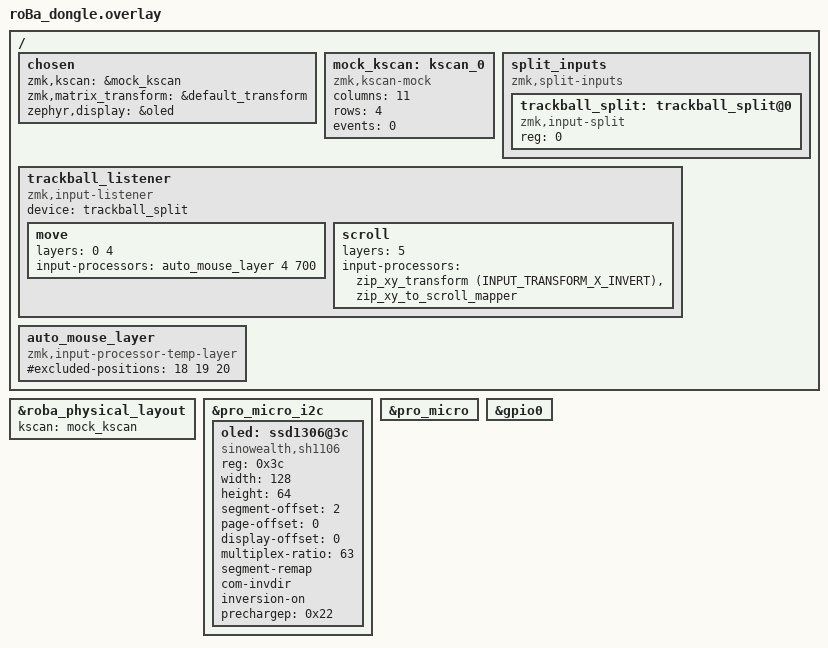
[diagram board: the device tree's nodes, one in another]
#include <dt-bindings/zmk/matrix_transform.h>
#include <dt-bindings/zmk/input_transform.h>
#include <input/processors.dtsi>
#include "roBa.dtsi"

/ {
    chosen {
        zmk,kscan = &mock_kscan;
        zmk,matrix_transform = &default_transform;
        zephyr,display = &oled;
    };

    mock_kscan: kscan_0 {
        compatible = "zmk,kscan-mock";
        columns = <11>;
        rows = <4>;
        events = <0>;
    };

    /* トラックボール信号の受け皿 (ドングル側) */
    split_inputs {
        compatible = "zmk,split-inputs";
        #address-cells = <1>;
        #size-cells = <0>;
        
        trackball_split: trackball_split@0 {
            compatible = "zmk,input-split";
            reg = <0>;
        };
    };

    /* リスナー定義 (wave10-F: restore the original automouse/scroll
     * behaviour in ZMK-main input-processor form. The external-driver
     * properties automouse-layer=<4> / scroll-layers=<5> and
     * CONFIG_PMW3610_AUTOMOUSE_TIMEOUT_MS=700 were lost in the move
     * to the in-tree driver; layer indices are this repo's keymap
     * order: 0 default, 4 MOUSE, 5 SCROLL.) */
    trackball_listener {
        compatible = "zmk,input-listener";
        device = <&trackball_split>;
        status = "okay";

        move {
            layers = <0 4>;
            input-processors = <&auto_mouse_layer 4 700>;
        };

        scroll {
            layers = <5>;
            /* original: CONFIG_PMW3610_INVERT_SCROLL_X=y */
            input-processors = <&zip_xy_transform (INPUT_TRANSFORM_X_INVERT)>, <&zip_xy_to_scroll_mapper>;
        };
    };

    auto_mouse_layer: auto_mouse_layer {
        compatible = "zmk,input-processor-temp-layer";
        #input-processor-cells = <2>;
        /* Mouse-button positions in the MOUSE layer (MB1/MB3/MB2 at
         * positions 18/19/20) must not dismiss the temporary layer. */
        #excluded-positions = <18 19 20>;
    };
};

/* The shared physical layout points at &kscan0, which the dongle does
 * not have; point it at the mock kscan instead (wave10-F). Without
 * this, the restored physical layout breaks the dongle build and
 * ZMK Studio on the dongle has no layout. */
&roba_physical_layout {
    kscan = <&mock_kscan>;
};

&pro_micro_i2c {
    status = "okay";
    oled: ssd1306@3c {
        compatible = "sinowealth,sh1106";
        reg = <0x3c>;
        width = <128>;
        height = <64>;
        segment-offset = <2>;
        page-offset = <0>;
        display-offset = <0>;
        multiplex-ratio = <63>;
        segment-remap;
        com-invdir;
        inversion-on;
        prechargep = <0x22>;
    };
};

xiao_d: &pro_micro {};
gpio0: &gpio0 {};
